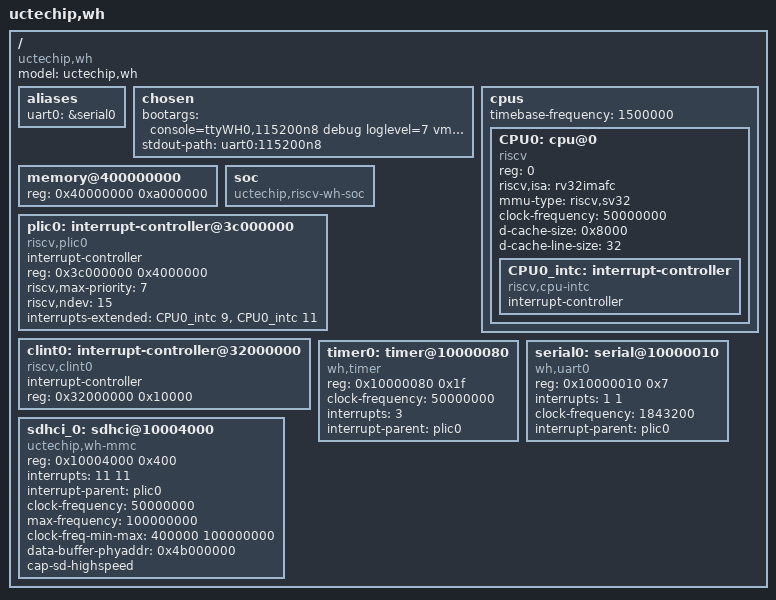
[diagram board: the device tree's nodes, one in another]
/dts-v1/;

/ {
	#address-cells = <1>;
	#size-cells = <1>;
	compatible = "uctechip,wh";
	model = "uctechip,wh";

	aliases {
		uart0 = &serial0;
	};

	chosen {
		bootargs = "console=ttyWH0,115200n8 debug loglevel=7 vmalloc=10M vmalloc=10M root=/dev/mmcblk0p2 rw sync rootfstype=ext4 rootdelay=2";
		stdout-path = "uart0:115200n8";
	};

	cpus {
		#address-cells = <1>;
		#size-cells = <0>;
		timebase-frequency = <1500000>;
		CPU0: cpu@0 {
			device_type = "cpu";
			reg = <0>;
			status = "okay";
			compatible = "riscv";
			riscv,isa = "rv32imafc";
			mmu-type = "riscv,sv32";
			clock-frequency = <50000000>;
			d-cache-size = <0x8000>;
			d-cache-line-size = <32>;
			CPU0_intc: interrupt-controller {
				#interrupt-cells = <1>;
				interrupt-controller;
				compatible = "riscv,cpu-intc";
			};
		};
	};

	memory@400000000 {
		device_type = "memory";
		reg = <0x40000000 0xa000000>;
	};

	soc {
		#address-cells = <1>;
		#size-cells = <1>;
		compatible = "uctechip,riscv-wh-soc";
		ranges;
    };
	
	plic0: interrupt-controller@3c000000 {
		compatible = "riscv,plic0";
		#address-cells = <1>;
		#interrupt-cells = <1>;
		interrupt-controller;
		reg = <0x3c000000 0x4000000>;
		riscv,max-priority = <7>;
		riscv,ndev=<15>;
		interrupts-extended = <&CPU0_intc 9 &CPU0_intc 11>;
	};

	clint0: interrupt-controller@32000000 {
		compatible = "riscv,clint0";
		#address-cells = <1>;
		#interrupt-cells = <1>;
		interrupt-controller;
		reg = <0x32000000 0x10000>;
	};
	
	timer0: timer@10000080 {
        compatible = "wh,timer";
      	reg = <0x10000080 0x1f>;
      	clock-frequency = <50000000>;
        interrupts = <3>;
       	interrupt-parent = <&plic0>;
    };

   
	serial0: serial@10000010 {
		compatible = "wh,uart0";
		reg = <0x10000010 0x7>;
		interrupts = <1 1>;
		clock-frequency = <1843200>;
		interrupt-parent = <&plic0>;
	};

	sdhci_0: sdhci@10004000 {
                compatible = "uctechip,wh-mmc";
                reg = <0x10004000 0x400>;
                interrupts = <11 11>;
                interrupt-parent = <&plic0>;
                clock-frequency = <50000000>;
                max-frequency = <100000000>;
                clock-freq-min-max = <400000 100000000>;
                data-buffer-phyaddr = <0x4b000000>;
		cap-sd-highspeed;
        };

};
